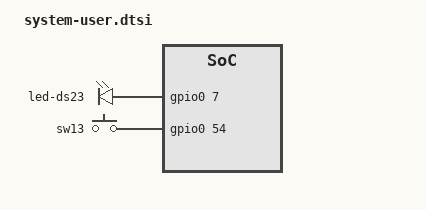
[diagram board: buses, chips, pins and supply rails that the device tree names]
/include/ "system-conf.dtsi"
/ {
gpio-leds {
    compatible = "gpio-leds";
    led-ds23 {
        label = "led-ds23";
        // gpios = <&ps7_gpio_0 7 0>;
        gpios = <&gpio0 7 0>;
        default-state = "on";
        linux,default-trigger = "heartbeat";
    };
};

gpio-keys {
    compatible = "gpio-keys";
    #address-cells = <1>;
    #size-cells = <0>;
    autorepeat;
//    sw14 {
//        label = "sw14";
//        gpios = <&ps7_gpio_0 12 0>;
//        linux,code = <108>; /* down */
//        gpio-key,wakeup;
//        autorepeat;
//    };
    sw13 {
        label = "sw13";
        gpios = <&gpio0 54 0>;
        linux,code = <103>; /* up */
        gpio-key,wakeup;
        autorepeat;
    };
};

};
